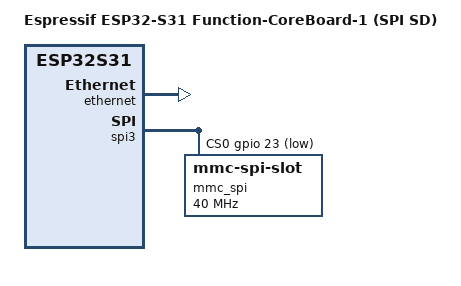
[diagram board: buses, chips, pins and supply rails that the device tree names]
// SPDX-License-Identifier: GPL-2.0+
/*
 * ESP32-S31 Function-CoreBoard-1 with SPI microSD Device Tree Source
 * Author: Marco Müller <hello@annoyedmilk.ch>
 *
 * Same on-board Ethernet / USB / Wi-Fi as function_coreboard_1, but the J2
 * SDMMC pads are wired as an SPI microSD socket (CLK/CMD/D0/D3) and driven
 * from Linux with GPSPI3 + mmc_spi.
 */
/dts-v1/;
#include "esp32s31.dtsi"
#include <dt-bindings/gpio/gpio.h>

/ {
	model = "Espressif ESP32-S31 Function-CoreBoard-1 (SPI SD)";
	compatible = "esp,esp32s31-function-coreboard-1-spi-sd",
		     "esp,esp32s31-function-coreboard-1", "esp,esp32s31";

	chosen {
		linux,initrd-start = <0x50800000>;
		linux,initrd-end = <0x50A00000>;
		stdout-path = "serial0:115200n8";

		framebuffer: framebuffer@50f40000 {
			compatible = "simple-framebuffer";
			reg = <0x50f40000 (320 * 240 * 2)>;
			width = <320>;
			height = <240>;
			stride = <(320 * 2)>;
			format = "r5g6b5";
			memory-region = <&fb_region>;
		};
	};

	ethernet: ethernet@2f060000 {
		compatible = "esp,esp32s31-eth";
		reg = <0x2f060000 0x18000>, <0x20586018 0x8>;
		reg-names = "ipc", "doorbell";
		interrupt-parent = <&clic>;
		interrupts = <36 67 IRQ_TYPE_LEVEL_HIGH>;
	};
};

/* Native SDMMC stays off; SPI owns the same header pads. */
&sdmmc0 { status = "disabled"; };

/*
 * Espressif SDSPI mapping on the J2 SDMMC pads:
 *   CLK=SCLK GPIO24, CMD=MOSI GPIO25, D0=MISO GPIO20, D3=CS GPIO23.
 * XTAL (40 MHz) clocks GPSPI3; spi-max-frequency rides that ceiling.
 */
&spi3 {
	status = "okay";
	esp,sck-pin = <24>;
	esp,mosi-pin = <25>;
	esp,miso-pin = <20>;
	cs-gpios = <&gpio 23 GPIO_ACTIVE_LOW>;

	mmc_spi: mmc-slot@0 {
		compatible = "mmc-spi-slot";
		reg = <0>;
		spi-max-frequency = <40000000>;
		voltage-ranges = <3300 3300>;
		broken-cd;
	};
};
